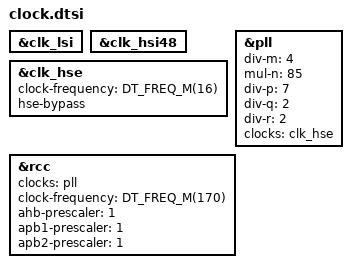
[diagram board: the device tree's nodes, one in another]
/*
 * Copyright (C) Frickly Systems GmbH
 * Copyright (C) MBition GmbH
 *
 * SPDX-License-Identifier: Apache-2.0
 */


&clk_lsi {
    status = "okay";
};

&clk_hsi48 {
    status = "okay";
};

&clk_hse {
    clock-frequency = <DT_FREQ_M(16)>;
    hse-bypass;
    status = "okay";
};

&pll {
    div-m = <4>;
    mul-n = <85>;
    div-p = <7>;
    div-q = <2>;
    div-r = <2>;
    clocks = <&clk_hse>;
    status = "okay";
};

&rcc {
    clocks = <&pll>;
    clock-frequency = <DT_FREQ_M(170)>;
    ahb-prescaler = <1>;
    apb1-prescaler = <1>;
    apb2-prescaler = <1>;
};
